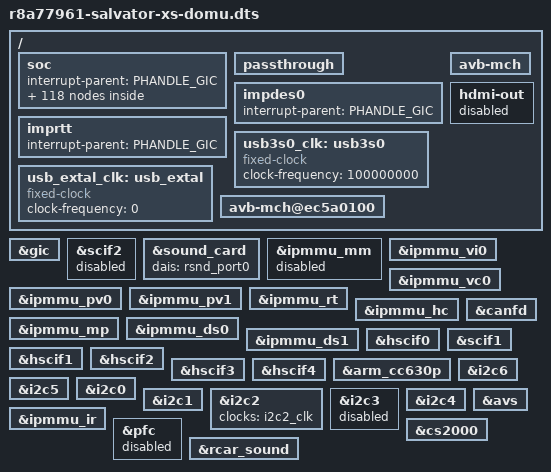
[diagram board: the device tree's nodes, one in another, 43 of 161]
// SPDX-License-Identifier: GPL-2.0
/*
 * Device Tree Source for the Salvator-X 2nd version board with R-Car M3-W+
 *
 * Copyright (C) 2018 Renesas Electronics Corp.
 */

/dts-v1/;
#include "r8a77961-salvator-xs.dts"

/*
 * The device tree compiler (DTC) is allocating the phandle from 1 to
 * onwards. Reserve a high value for the GIC phandle.
 */
#define PHANDLE_GIC (65000)

/ {
	soc {
		/* This must point to Xen interrupt-parent */
		interrupt-parent = <PHANDLE_GIC>;
	};

	passthrough {
	};

	/*
	 * When creating DT for the guest domain Xen inserts only dummy CPU nodes.
	 * And the number of these inserted CPU nodes is equal to the number of
	 * vCPUs assigned to this domain. All CPU properties which original DT has,
	 * such as OPP, clock, regulator, etc are not passed to the guest’s DT.
	 *
	 * Example of guest vCPU node:
	 *
	 * cpu@0 {
	 *     device_type = "cpu";
	 *     compatible = "arm,armv8";
	 *     enable-method = "psci";
	 *     reg = <0x0>;
	 * };
	 *
	 * This results in the fact that all features expecting a57_x or a53_x
	 * CPU nodes to be present get broken. This is why we have to explicitly
	 * remove the following.
	 */
	/delete-node/thermal-zones;
	/delete-node/pmu_a57;
	/delete-node/pmu_a53;
	/delete-node/cpus;
	/delete-node/psci;
	/delete-node/aliases;
	/delete-node/timer;

//	/delete-node/opp-table0;
//	/delete-node/opp-table1;
//	/delete-node/opp-table2;
//	/delete-node/opp-table3;
//	/delete-node/opp-table4;
//	/delete-node/opp-table5;
//	/delete-node/opp-table6;
//	/delete-node/opp-table7;
//	/delete-node/opp-table10;
};

/delete-node/&adsp;

/* Xen will provide its own GIC, mask ours */
&gic {
	compatible = "";
};

&scif2 {
	status = "disabled";
};

/ {
	impdes0		{
		interrupt-parent = <PHANDLE_GIC>;
	};
	imprtt		{
		interrupt-parent = <PHANDLE_GIC>;
	};
};

/* ============================ Devices config section =====================*/
/ {
	avb-mch /* avb-mch*/
	{
		/delete-property/clocks;
		/delete-property/resets;
		/delete-property/power-domains;
	};

	hdmi-out {
		status = "disabled";
	};
	/* External USB clocks - can be overridden by the board */
	usb3s0_clk: usb3s0 {
		compatible = "fixed-clock";
		#clock-cells = <0>;
		clock-frequency = <100000000>;
	};

	usb_extal_clk: usb_extal {
		compatible = "fixed-clock";
		#clock-cells = <0>;
		clock-frequency = <0>;
	};

};

/ {
	soc {
	fixed_serial_clk: fixed_serial_clk {
		compatible = "fixed-clock";
		#clock-cells = <0>;
		clock-frequency = <266666656>;
	};
	fixed_clk_scif1: fixed_clk_scif1 {
		compatible = "fixed-clock";
		#clock-cells = <0>;
		clock-frequency = <66666664>;
	};


	imp0  /* imp0*/
	{
		/delete-property/clocks;
		/delete-property/resets;
		/delete-property/power-domains;
	};
	imp1  /* imp1*/
	{
		/delete-property/clocks;
		/delete-property/resets;
		/delete-property/power-domains;
	};
	imp2  /* imp2*/
	{
		/delete-property/clocks;
		/delete-property/resets;
		/delete-property/power-domains;
	};
	impc0  /* impc0*/
	{
		/delete-property/clocks;
		/delete-property/resets;
		/delete-property/power-domains;
	};
	impdm0	/* impdm0*/
	{
		/delete-property/clocks;
		/delete-property/resets;
		/delete-property/power-domains;
	};
	imprtt	/* imprtt*/
	{
		/delete-property/clocks;
		/delete-property/resets;
		/delete-property/power-domains;
	};
	impsc0	/* impsc0*/
	{
		/delete-property/clocks;
		/delete-property/resets;
		/delete-property/power-domains;
	};
	impsc1	/* impsc1*/
	{
		/delete-property/clocks;
		/delete-property/resets;
		/delete-property/power-domains;
	};
	impsl0	/* impsl0*/
	{
		/delete-property/clocks;
		/delete-property/resets;
		/delete-property/power-domains;
	};
	imr-lx4@fe860000  /* imr-lx4@fe860000*/
	{
		/delete-property/clocks;
		/delete-property/resets;
		/delete-property/power-domains;
	};
	imr-lx4@fe870000  /* imr-lx4@fe870000*/
	{
		/delete-property/clocks;
		/delete-property/resets;
		/delete-property/power-domains;
	};
	imr-lx4@fe880000  /* imr-lx4@fe880000*/
	{
		/delete-property/clocks;
		/delete-property/resets;
		/delete-property/power-domains;
	};
	imr-lx4@fe890000  /* imr-lx4@fe890000*/
	{
		/delete-property/clocks;
		/delete-property/resets;
		/delete-property/power-domains;
	};

	mfis-as {
		status = "disabled";
	};
	};
};

	&sound_card {
		dais = <&rsnd_port0>;
	};

/delete-node/&sysc;
/delete-node/&cpg;
/delete-node/&rst;
/{
	soc {
// This is autogenerated dts part
adsp@ec800000
{
  /delete-property/clocks;
  /delete-property/resets;
  /delete-property/power-domains;
};
avb-mch@ec5a0100
{
  /delete-property/clocks;
  /delete-property/resets;
  /delete-property/power-domains;
};
avs@e60a013c
{
  /delete-property/clocks;
  /delete-property/resets;
  /delete-property/power-domains;
};
clk_multiplier@4f
{
  /delete-property/clocks;
  /delete-property/resets;
  /delete-property/power-domains;
};
clock-controller@e6150000
{
  /delete-property/clocks;
  /delete-property/resets;
  /delete-property/power-domains;
};
clock-generator@6a
{
  /delete-property/clocks;
  /delete-property/resets;
  /delete-property/power-domains;
};
codec@10
{
  /delete-property/clocks;
  /delete-property/resets;
  /delete-property/power-domains;
};
cpu@0
{
  /delete-property/clocks;
  /delete-property/resets;
  /delete-property/power-domains;
};
cpu@1
{
  /delete-property/clocks;
  /delete-property/resets;
  /delete-property/power-domains;
};
cpu@100
{
  /delete-property/clocks;
  /delete-property/resets;
  /delete-property/power-domains;
};
cpu@101
{
  /delete-property/clocks;
  /delete-property/resets;
  /delete-property/power-domains;
};
cpu@102
{
  /delete-property/clocks;
  /delete-property/resets;
  /delete-property/power-domains;
};
cpu@103
{
  /delete-property/clocks;
  /delete-property/resets;
  /delete-property/power-domains;
};
csi2@fea80000
{
  /delete-property/clocks;
  /delete-property/resets;
  /delete-property/power-domains;
	status = "disabled";
};
csi2@feaa0000
{
  /delete-property/clocks;
  /delete-property/resets;
  /delete-property/power-domains;
	status = "disabled";
};
display@feb00000
{
  /delete-property/clocks;
  /delete-property/resets;
  /delete-property/power-domains;
  status = "disabled";
};
dma-controller@e65a0000
{
  /delete-property/clocks;
  /delete-property/resets;
  /delete-property/power-domains;
  status = "disabled";
};
dma-controller@e65b0000
{
  /delete-property/clocks;
  /delete-property/resets;
  /delete-property/power-domains;
  status = "disabled";
};
dma-controller@e6700000
{
  /delete-property/clocks;
  /delete-property/resets;
  /delete-property/power-domains;
};
dma-controller@e7300000
{
  /delete-property/clocks;
  /delete-property/resets;
  /delete-property/power-domains;
};
dma-controller@e7310000
{
  /delete-property/clocks;
  /delete-property/resets;
  /delete-property/power-domains;
};
dma-controller@ec700000
{
  /delete-property/clocks;
  /delete-property/resets;
  /delete-property/power-domains;
};
dma-controller@ec720000
{
  /delete-property/clocks;
  /delete-property/resets;
  /delete-property/power-domains;
};
dma-controller@ffc10000
{
  /delete-property/clocks;
  /delete-property/resets;
  /delete-property/power-domains;
};
ethernet@e6800000
{
  /delete-property/clocks;
  /delete-property/resets;
  /delete-property/power-domains;
};
fcp@fea27000
{
  /delete-property/clocks;
  /delete-property/resets;
  /delete-property/power-domains;
  status = "disabled";
};
fcp@fea2f000
{
  /delete-property/clocks;
  /delete-property/resets;
  /delete-property/power-domains;
  status = "disabled";
};
fcp@fea37000
{
  /delete-property/clocks;
  /delete-property/resets;
  /delete-property/power-domains;
  status = "disabled";
};
fdpm@fe940000
{
  /delete-property/clocks;
  /delete-property/resets;
  /delete-property/power-domains;
};
gpio@e6050000
{
  /delete-property/clocks;
  /delete-property/resets;
  /delete-property/power-domains;
  status = "disabled";
};
gpio@e6051000
{
  /delete-property/clocks;
  /delete-property/resets;
  /delete-property/power-domains;
  status = "disabled";
};
gpio@e6052000
{
  /delete-property/clocks;
  /delete-property/resets;
  /delete-property/power-domains;
  status = "disabled";
};
gpio@e6053000
{
  /delete-property/clocks;
  /delete-property/resets;
  /delete-property/power-domains;
  status = "disabled";
};
gpio@e6054000
{
  /delete-property/clocks;
  /delete-property/resets;
  /delete-property/power-domains;
  status = "disabled";
};

gpio@e6055000
{
  /delete-property/clocks;
  /delete-property/resets;
  /delete-property/power-domains;
  /delete-property/gpio-ranges;
  status = "okay";
};
gpio@e6055400
{
  /delete-property/clocks;
  /delete-property/resets;
  /delete-property/power-domains;
  /delete-property/gpio-ranges;
  status = "okay";
};
gpio@e6055800
{
  /delete-property/clocks;
  /delete-property/resets;
  /delete-property/power-domains;
  status = "disabled";
};
gsx@fd000000
{
  /delete-property/clocks;
  /delete-property/resets;
  /delete-property/power-domains;
  status = "disabled";
};
hdmi@fead0000
{
  /delete-property/clocks;
  /delete-property/resets;
  /delete-property/power-domains;
  status = "disabled";
};
i2c@e60b0000
{
  /delete-property/clocks;
  /delete-property/resets;
  /delete-property/power-domains;
  status = "disabled";
};
i2c@e66d8000
{
  /delete-property/clocks;
  /delete-property/resets;
  /delete-property/power-domains;
  status = "disabled";
};
imp0
{
  /delete-property/clocks;
  /delete-property/resets;
  /delete-property/power-domains;
};
imp1
{
  /delete-property/clocks;
  /delete-property/resets;
  /delete-property/power-domains;
};
impc0
{
  /delete-property/clocks;
  /delete-property/resets;
  /delete-property/power-domains;
};
impdes0
{
  /delete-property/clocks;
  /delete-property/resets;
  /delete-property/power-domains;
  status = "disabled";
};
impdm0
{
  /delete-property/clocks;
  /delete-property/resets;
  /delete-property/power-domains;
};
imprtt
{
  /delete-property/clocks;
  /delete-property/resets;
  /delete-property/power-domains;
};
impsc0
{
  /delete-property/clocks;
  /delete-property/resets;
  /delete-property/power-domains;
};
lvds@feb90000
{
  /delete-property/clocks;
  /delete-property/resets;
  /delete-property/power-domains;
  status = "disabled";
};
mmc@ee100000
{
  clocks = <&i2c2_clk>;
  /delete-property/resets;
  /delete-property/power-domains;
};
mmc@ee120000
{
  /delete-property/clocks;
  /delete-property/resets;
  /delete-property/power-domains;
  status = "disabled";
};
interrupt-controller@f1010000
{
  /delete-property/clocks;
  /delete-property/resets;
  /delete-property/power-domains;
};
mmc@ee140000
{
  /delete-property/clocks;
  /delete-property/resets;
  /delete-property/power-domains;
  status = "disabled";
};
mmc@ee160000
{
  /delete-property/clocks;
  /delete-property/resets;
  /delete-property/power-domains;
  status = "disabled";
};
pcie@ee800000
{
  /delete-property/clocks;
  /delete-property/resets;
  /delete-property/power-domains;
};
pcie@fe000000
{
  /delete-property/clocks;
  /delete-property/resets;
  /delete-property/power-domains;
};
pwm@e6e35000
{
  /delete-property/clocks;
  /delete-property/resets;
  /delete-property/power-domains;
  status = "disabled";
};

pwm@e6e30000
{
  /delete-property/clocks;
  /delete-property/resets;
  /delete-property/power-domains;
  status = "disabled";
};

can@e6c30000
{
  /delete-property/clocks;
  /delete-property/assigned-clocks;
  /delete-property/resets;
  /delete-property/power-domains;
};

can@e6c38000
{
  /delete-property/clocks;
  /delete-property/assigned-clocks;
  /delete-property/resets;
  /delete-property/power-domains;
};

can@e66c0000
{
  /delete-property/clocks;
  /delete-property/resets;
  /delete-property/power-domains;
};

pwm@e6e33000
{
  /delete-property/clocks;
  /delete-property/resets;
  /delete-property/power-domains;
};

pwm@e6e34000
{
  /delete-property/clocks;
  /delete-property/resets;
  /delete-property/power-domains;
};

pwm@e6e36000
{
  /delete-property/clocks;
  /delete-property/resets;
  /delete-property/power-domains;
};

pwm@e6e31000
{
  /delete-property/clocks;
  /delete-property/resets;
  /delete-property/power-domains;
};
pwm@e6e32000
{
  /delete-property/clocks;
  /delete-property/resets;
  /delete-property/power-domains;
};
rpc0@ee200000
{
  /delete-property/clocks;
  /delete-property/resets;
  /delete-property/power-domains;
};
serial@e6c40000
{
  /delete-property/clocks;
  /delete-property/resets;
  /delete-property/power-domains;
};
serial@e6c50000
{
  /delete-property/clocks;
  /delete-property/resets;
  /delete-property/power-domains;
};

serial@e6f30000
{
  /delete-property/clocks;
  /delete-property/resets;
  /delete-property/power-domains;
};

spi@e6ea0000
{
  /delete-property/clocks;
  /delete-property/resets;
  /delete-property/power-domains;
};
spi@e6e90000
{
  /delete-property/clocks;
  /delete-property/resets;
  /delete-property/power-domains;
};

mlp@ec520000
{
  /delete-property/clocks;
  /delete-property/resets;
  /delete-property/power-domains;
};

spi@e6c00000
{
  /delete-property/clocks;
  /delete-property/resets;
  /delete-property/power-domains;
};
spi@e6c10000
{
  /delete-property/clocks;
  /delete-property/resets;
  /delete-property/power-domains;
};
serial@e6e60000
{
  /delete-property/clocks;
  /delete-property/resets;
  /delete-property/power-domains;
};

serial@e6e88000
{
  /delete-property/clocks;
  /delete-property/resets;
  /delete-property/power-domains;
};
sound@ec500000
{
  /delete-property/clocks;
  /delete-property/resets;
  /delete-property/power-domains;
};
thermal@e6198000
{
  /delete-property/clocks;
  /delete-property/resets;
  /delete-property/power-domains;
  status = "disabled";
};
usb-phy@e65ee000
{

	clocks = <&usb3s0_clk>,
				 <&usb_extal_clk>;
  /delete-property/resets;
  /delete-property/power-domains;
};
usb-phy@ee080200
{
  /delete-property/clocks;
  /delete-property/resets;
  /delete-property/power-domains;
};
usb-phy@ee0a0200
{
  /delete-property/clocks;
  /delete-property/resets;
  /delete-property/power-domains;
};
usb@e6590000
{
  /delete-property/clocks;
  /delete-property/resets;
  /delete-property/power-domains;
  status = "disabled";
};
usb@ee000000
{
  /delete-property/clocks;
  /delete-property/resets;
  /delete-property/power-domains;
  status = "disabled";
};
usb@ee020000
{
  /delete-property/clocks;
  /delete-property/resets;
  /delete-property/power-domains;
};
usb@ee080000
{
  /delete-property/clocks;
  /delete-property/resets;
  /delete-property/power-domains;
  status = "disabled";
};
usb@ee080100
{
  /delete-property/clocks;
  /delete-property/resets;
  /delete-property/power-domains;
  status = "disabled";
};
usb@ee0a0000
{
  /delete-property/clocks;
  /delete-property/resets;
  /delete-property/power-domains;
  status = "disabled";
};
usb@ee0a0100
{
  /delete-property/clocks;
  /delete-property/resets;
  /delete-property/power-domains;
  status = "disabled";
};
vcp4@fe8d0000
{
  /delete-property/clocks;
  /delete-property/resets;
  /delete-property/power-domains;
};
vcp4@fe8df000
{
  /delete-property/clocks;
  /delete-property/resets;
  /delete-property/power-domains;
};
vcp4@fe900000
{
  /delete-property/clocks;
  /delete-property/resets;
  /delete-property/power-domains;
};
vcp4@fe90f000
{
  /delete-property/clocks;
  /delete-property/resets;
  /delete-property/power-domains;
};
vcp4@fe910000
{
  /delete-property/clocks;
  /delete-property/resets;
  /delete-property/power-domains;
};
video@e6ef0000
{
  /delete-property/clocks;
  /delete-property/resets;
  /delete-property/power-domains;
};
video@e6ef1000
{
  /delete-property/clocks;
  /delete-property/resets;
  /delete-property/power-domains;
};
video@e6ef2000
{
  /delete-property/clocks;
  /delete-property/resets;
  /delete-property/power-domains;
  status = "disabled";
};
video@e6ef3000
{
  /delete-property/clocks;
  /delete-property/resets;
  /delete-property/power-domains;
  status = "disabled";
};
video@e6ef4000
{
  /delete-property/clocks;
  /delete-property/resets;
  /delete-property/power-domains;
  status = "disabled";
};
video@e6ef5000
{
  /delete-property/clocks;
  /delete-property/resets;
  /delete-property/power-domains;
  status = "disabled";
};
video@e6ef6000
{
  /delete-property/clocks;
  /delete-property/resets;
  /delete-property/power-domains;
  status = "disabled";
};
video@e6ef7000
{
  /delete-property/clocks;
  /delete-property/resets;
  /delete-property/power-domains;
  status = "disabled";
};
vsp@fea20000
{
  /delete-property/clocks;
  /delete-property/resets;
  /delete-property/power-domains;
  status = "disabled";
};
vsp@fea28000
{
  /delete-property/clocks;
  /delete-property/resets;
  /delete-property/power-domains;
  status = "disabled";
};
vsp@fea30000
{
  /delete-property/clocks;
  /delete-property/resets;
  /delete-property/power-domains;
  status = "disabled";
};
vspm@fe960000
{
  /delete-property/clocks;
  /delete-property/resets;
  /delete-property/power-domains;
};
vspm@fe9a0000
{
  /delete-property/clocks;
  /delete-property/resets;
  /delete-property/power-domains;
};
watchdog@e6020000
{
  /delete-property/clocks;
  /delete-property/resets;
  /delete-property/power-domains;
  status = "disabled";
};
};
};
/ {
avb-mch@ec5a0100
{
/delete-property/clocks;
/delete-property/resets;
/delete-property/power-domains;
};
};

&ipmmu_mm {
/delete-property/power-domains;
	status = "disabled";
};

&ipmmu_vi0 {
/delete-property/power-domains;
};

&ipmmu_vc0 {
/delete-property/power-domains;
};

&ipmmu_pv0 {
/delete-property/power-domains;
};

&ipmmu_pv1 {
/delete-property/power-domains;
};

&ipmmu_rt {
/delete-property/power-domains;
};

&ipmmu_hc {
/delete-property/power-domains;
};

&ipmmu_mp {
/delete-property/power-domains;
};

&ipmmu_ds0 {
/delete-property/power-domains;
};

&ipmmu_ds1 {
/delete-property/power-domains;
};
 &canfd {
	 /delete-property/assigned-clocks;
};
&hscif0 {
	clocks = <&fixed_serial_clk>, <&fixed_serial_clk>,
		   <&fixed_serial_clk>;

  /delete-property/resets;
  /delete-property/power-domains;

};
&scif1 /* serial@e6e68000*/
{
	clocks = <&fixed_clk_scif1>,
		   <&fixed_clk_scif1>,
		   <&fixed_clk_scif1>;
	/delete-property/resets;
	/delete-property/power-domains;
};

&hscif1 {
	clocks = <&fixed_serial_clk>, <&fixed_serial_clk>,
		   <&fixed_serial_clk>;
  /delete-property/resets;
  /delete-property/power-domains;

};
&hscif2 {
  /delete-property/clocks;
  /delete-property/resets;
  /delete-property/power-domains;

};
&hscif3 {
  /delete-property/clocks;
  /delete-property/resets;
  /delete-property/power-domains;

};

&hscif4 {
  /delete-property/clocks;
  /delete-property/resets;
  /delete-property/power-domains;

};
&arm_cc630p {
  /delete-property/power-domains;
};
&i2c6 {
  /delete-property/clocks;
  /delete-property/resets;
  /delete-property/power-domains;

};
&i2c5 {
  /delete-property/clocks;
  /delete-property/resets;
  /delete-property/power-domains;

};

&i2c0 {
  /delete-property/clocks;
  /delete-property/resets;
  /delete-property/power-domains;

};
&i2c1 {
  /delete-property/clocks;
  /delete-property/resets;
  /delete-property/power-domains;

};
&i2c2 {
  /delete-property/power-domains;
	/delete-property/dmas;
	/delete-property/dma-names;

	clocks = <&i2c2_clk>;

};
&i2c3 {
  /delete-property/clocks;
  /delete-property/resets;
  /delete-property/power-domains;

status = "disabled";
};
&i2c4 {
  /delete-property/clocks;
  /delete-property/power-domains;

};
&avs {
  /delete-property/clocks;
  /delete-property/resets;
  /delete-property/power-domains;
  /delete-property/target_devices;

};

&ipmmu_ir {
  /delete-property/clocks;
  /delete-property/resets;
  /delete-property/power-domains;

};

&pfc {
	status = "disabled";
};

&cs2000
{
	/delete-property/clocks;
	/delete-property/clock-names;
};
&rcar_sound /* sound@ec500000*/
{
	/delete-property/power-domains;
};

// End of autogenerated dts part
